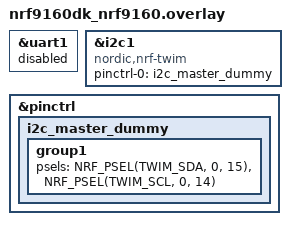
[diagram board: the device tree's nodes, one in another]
&uart1 {
    status = "disabled";
};

&i2c1 {
    status = "okay";
    compatible = "nordic,nrf-twim";
    pinctrl-0 = <&i2c_master_dummy>;
    pinctrl-names = "default";
};

&pinctrl {
    i2c_master_dummy: i2c_master_dummy {
        group1 {
            psels = <NRF_PSEL(TWIM_SDA, 0, 15)>,
                <NRF_PSEL(TWIM_SCL, 0, 14)>;
        };
    };
};

/delete-node/ &pcal6408a;
